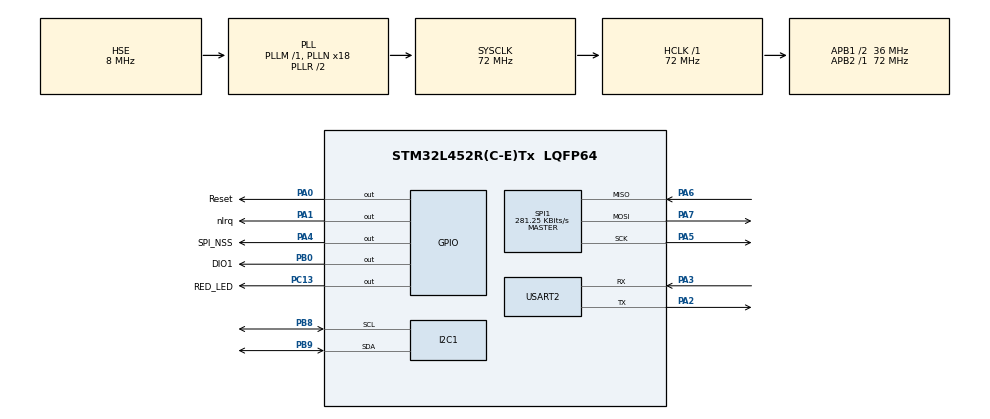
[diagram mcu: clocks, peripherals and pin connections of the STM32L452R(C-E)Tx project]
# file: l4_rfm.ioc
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I2C1.Timing=0x10808DD3
Mcu.Family=STM32L4
Mcu.Name=STM32L452R(C-E)Tx
Mcu.Package=LQFP64
NVIC.PriorityGroup=NVIC_PRIORITYGROUP_4
PA0.GPIO_Label=Reset
PA0.GPIO_ModeDefaultOutputPP=GPIO_MODE_OUTPUT_PP
PA0.GPIO_PuPd=GPIO_NOPULL
PA0.GPIO_Speed=GPIO_SPEED_FREQ_LOW
PA0.PinState=GPIO_PIN_RESET
PA0.Signal=GPIO_Output
PA1.GPIO_Label=nIrq
PA1.GPIO_ModeDefaultOutputPP=GPIO_MODE_OUTPUT_PP
PA1.GPIO_PuPd=GPIO_NOPULL
PA1.GPIO_Speed=GPIO_SPEED_FREQ_LOW
PA1.PinState=GPIO_PIN_RESET
PA1.Signal=GPIO_Output
PA13\ (JTMS/SWDIO).Signal=SYS_JTMS-SWDIO
PA14\ (JTCK/SWCLK).Signal=SYS_JTCK-SWCLK
PA2.GPIO_Mode=GPIO_MODE_AF_PP
PA2.GPIO_ModeDefaultPP=GPIO_MODE_AF_PP
PA2.GPIO_PuPd=GPIO_NOPULL
PA2.GPIO_Speed=GPIO_SPEED_FREQ_VERY_HIGH
PA2.Mode=Asynchronous
PA2.Signal=USART2_TX
PA3.GPIO_Mode=GPIO_MODE_AF_PP
PA3.GPIO_ModeDefaultPP=GPIO_MODE_AF_PP
PA3.GPIO_PuPd=GPIO_NOPULL
PA3.GPIO_Speed=GPIO_SPEED_FREQ_VERY_HIGH
PA3.Mode=Asynchronous
PA3.Signal=USART2_RX
PA4.GPIO_Label=SPI_NSS
PA4.GPIO_ModeDefaultOutputPP=GPIO_MODE_OUTPUT_PP
PA4.GPIO_PuPd=GPIO_NOPULL
PA4.GPIO_Speed=GPIO_SPEED_FREQ_LOW
PA4.PinState=GPIO_PIN_RESET
PA4.Signal=GPIO_Output
PA5.Mode=Full_Duplex_Master
PA5.Signal=SPI1_SCK
PA6.Mode=Full_Duplex_Master
PA6.Signal=SPI1_MISO
PA7.Mode=Full_Duplex_Master
PA7.Signal=SPI1_MOSI
PB0.GPIO_Label=DIO1
PB0.GPIO_ModeDefaultOutputPP=GPIO_MODE_OUTPUT_PP
PB0.GPIO_PuPd=GPIO_NOPULL
PB0.GPIO_Speed=GPIO_SPEED_FREQ_LOW
PB0.PinState=GPIO_PIN_RESET
PB0.Signal=GPIO_Output
PB3\ (JTDO/TRACESWO).Signal=SYS_JTDO-SWO
PB8.Mode=I2C
PB8.Signal=I2C1_SCL
PB9.Mode=I2C
PB9.Signal=I2C1_SDA
PC13.GPIO_Label=RED_LED
PC13.GPIO_ModeDefaultOutputPP=GPIO_MODE_OUTPUT_PP
PC13.GPIO_PuPd=GPIO_NOPULL
PC13.GPIO_Speed=GPIO_SPEED_FREQ_LOW
PC13.PinState=GPIO_PIN_RESET
PC13.Signal=GPIO_Output
PC14-OSC32_IN\ (PC14).Mode=LSE-External-Oscillator
PC14-OSC32_IN\ (PC14).Signal=RCC_OSC32_IN
PC15-OSC32_OUT\ (PC15).Mode=LSE-External-Oscillator
PC15-OSC32_OUT\ (PC15).Signal=RCC_OSC32_OUT
PH0-OSC_IN\ (PH0).Mode=HSE-External-Oscillator
PH0-OSC_IN\ (PH0).Signal=RCC_OSC_IN
PH1-OSC_OUT\ (PH1).Mode=HSE-External-Oscillator
PH1-OSC_OUT\ (PH1).Signal=RCC_OSC_OUT
ProjectManager.HeapSize=0x200
ProjectManager.StackSize=0x400
ProjectManager.TargetToolchain=STM32CubeIDE
RCC.ADCFreq_Value=32000000
RCC.AHBFreq_Value=72000000
RCC.APB1CLKDivider=RCC_HCLK_DIV2
RCC.APB1Freq_Value=36000000
RCC.APB1TimFreq_Value=72000000
RCC.APB2Freq_Value=72000000
RCC.APB2TimFreq_Value=72000000
RCC.CortexFreq_Value=72000000
RCC.HCLKFreq_Value=72000000
RCC.HSE_VALUE=8000000
RCC.HSI48_VALUE=48000000
RCC.HSI_VALUE=16000000
RCC.I2C1CLockSelection=RCC_I2C1CLKSOURCE_SYSCLK
RCC.MSI_VALUE=4000000
RCC.PLLN=18
RCC.PLLSourceVirtual=RCC_PLLSOURCE_HSE
RCC.PREFETCH_ENABLE=1
RCC.SYSCLKFreq_VALUE=72000000
RCC.SYSCLKSource=RCC_SYSCLKSOURCE_PLLCLK
RCC.USBFreq_Value=32000000
RCC.VCOOutputFreq_Value=144000000
SPI1.BaudRatePrescaler=SPI_BAUDRATEPRESCALER_256
SPI1.CalculateBaudRate=281.25 KBits/s
SPI1.DataSize=SPI_DATASIZE_8BIT
SPI1.Direction=SPI_DIRECTION_2LINES
SPI1.Mode=SPI_MODE_MASTER
SPI1.VirtualType=VM_MASTER
USART2.VirtualMode-Asynchronous=VM_ASYNC
board=NUCLEO-L452RE

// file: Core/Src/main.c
/* USER CODE BEGIN Header */
/**
  ******************************************************************************
  * @file           : main.c
  * @brief          : Main program body
  ******************************************************************************
  * @attention
  *
  * <h2><center>&copy; Copyright (c) 2020 STMicroelectronics.
  * All rights reserved.</center></h2>
  *
  * This software component is licensed by ST under BSD 3-Clause license,
  * the "License"; You may not use this file except in compliance with the
  * License. You may obtain a copy of the License at:
  *                        opensource.org/licenses/BSD-3-Clause
  *
  ******************************************************************************
  */
/* USER CODE END Header */

#include "main.h"
#include "stm32l4xx_hal_conf.h"
#include "connection.h"
#include "string.h"

I2C_HandleTypeDef hi2c1;

SPI_HandleTypeDef hspi1;

UART_HandleTypeDef huart2;

void SystemClock_Config(void);
static void MX_GPIO_Init(void);
static void MX_USART2_UART_Init(void);
static void MX_SPI1_Init(void);
static void MX_I2C1_Init(void);

int main(void)
{
  /* USER CODE BEGIN 1 */
	HAL_StatusTypeDef ret;
	//	uint8_t buf[12];
		int16_t val;
		float temp_c;//,transfer=0,a,b;

  /* USER CODE END 1 */

  /* MCU Configuration--------------------------------------------------------*/

  /* Reset of all peripherals, Initializes the Flash interface and the Systick. */
  HAL_Init();

  /* Configure the system clock */
  SystemClock_Config();

  /* Initialize all configured peripherals */
  MX_GPIO_Init();
  MX_USART2_UART_Init();
  MX_SPI1_Init();
  MX_I2C1_Init();

  /* Infinite loop */
  while (1)
  {

    /* USER CODE BEGIN 3 */
//	 connection(&transfer);
	 connection();
  }
  /* USER CODE END 3 */
}

void SystemClock_Config(void)
{
  RCC_OscInitTypeDef RCC_OscInitStruct = {0};
  RCC_ClkInitTypeDef RCC_ClkInitStruct = {0};
  RCC_PeriphCLKInitTypeDef PeriphClkInit = {0};

  /** Initializes the CPU, AHB and APB busses clocks
  */
  RCC_OscInitStruct.OscillatorType = RCC_OSCILLATORTYPE_HSE;
  RCC_OscInitStruct.HSEState = RCC_HSE_ON;
  RCC_OscInitStruct.PLL.PLLState = RCC_PLL_ON;
  RCC_OscInitStruct.PLL.PLLSource = RCC_PLLSOURCE_HSE;
  RCC_OscInitStruct.PLL.PLLM = 1;
  RCC_OscInitStruct.PLL.PLLN = 18;
  RCC_OscInitStruct.PLL.PLLP = RCC_PLLP_DIV7;
  RCC_OscInitStruct.PLL.PLLQ = RCC_PLLQ_DIV2;
  RCC_OscInitStruct.PLL.PLLR = RCC_PLLR_DIV2;
  if (HAL_RCC_OscConfig(&RCC_OscInitStruct) != HAL_OK)
  {
    Error_Handler();
  }
  /** Initializes the CPU, AHB and APB busses clocks
  */
  RCC_ClkInitStruct.ClockType = RCC_CLOCKTYPE_HCLK|RCC_CLOCKTYPE_SYSCLK
                              |RCC_CLOCKTYPE_PCLK1|RCC_CLOCKTYPE_PCLK2;
  RCC_ClkInitStruct.SYSCLKSource = RCC_SYSCLKSOURCE_PLLCLK;
  RCC_ClkInitStruct.AHBCLKDivider = RCC_SYSCLK_DIV1;
  RCC_ClkInitStruct.APB1CLKDivider = RCC_HCLK_DIV2;
  RCC_ClkInitStruct.APB2CLKDivider = RCC_HCLK_DIV1;

  if (HAL_RCC_ClockConfig(&RCC_ClkInitStruct, FLASH_LATENCY_4) != HAL_OK)
  {
    Error_Handler();
  }
  PeriphClkInit.PeriphClockSelection = RCC_PERIPHCLK_USART2|RCC_PERIPHCLK_I2C1;
  PeriphClkInit.Usart2ClockSelection = RCC_USART2CLKSOURCE_PCLK1;
  PeriphClkInit.I2c1ClockSelection = RCC_I2C1CLKSOURCE_SYSCLK;
  if (HAL_RCCEx_PeriphCLKConfig(&PeriphClkInit) != HAL_OK)
  {
    Error_Handler();
  }
  /** Configure the main internal regulator output voltage
  */
  if (HAL_PWREx_ControlVoltageScaling(PWR_REGULATOR_VOLTAGE_SCALE1) != HAL_OK)
  {
    Error_Handler();
  }
}

static void MX_I2C1_Init(void)
{

  hi2c1.Instance = I2C1;
  hi2c1.Init.Timing = 0x10808DD3;
  hi2c1.Init.OwnAddress1 = 0;
  hi2c1.Init.AddressingMode = I2C_ADDRESSINGMODE_7BIT;
  hi2c1.Init.DualAddressMode = I2C_DUALADDRESS_DISABLE;
  hi2c1.Init.OwnAddress2 = 0;
  hi2c1.Init.OwnAddress2Masks = I2C_OA2_NOMASK;
  hi2c1.Init.GeneralCallMode = I2C_GENERALCALL_DISABLE;
  hi2c1.Init.NoStretchMode = I2C_NOSTRETCH_DISABLE;
  if (HAL_I2C_Init(&hi2c1) != HAL_OK)
  {
    Error_Handler();
  }
  /** Configure Analogue filter
  */
  if (HAL_I2CEx_ConfigAnalogFilter(&hi2c1, I2C_ANALOGFILTER_ENABLE) != HAL_OK)
  {
    Error_Handler();
  }
  /** Configure Digital filter
  */
  if (HAL_I2CEx_ConfigDigitalFilter(&hi2c1, 0) != HAL_OK)
  {
    Error_Handler();
  }

}

static void MX_SPI1_Init(void)
{

  /* SPI1 parameter configuration*/
  hspi1.Instance = SPI1;
  hspi1.Init.Mode = SPI_MODE_MASTER;
  hspi1.Init.Direction = SPI_DIRECTION_2LINES;
  hspi1.Init.DataSize = SPI_DATASIZE_8BIT;
  hspi1.Init.CLKPolarity = SPI_POLARITY_LOW;
  hspi1.Init.CLKPhase = SPI_PHASE_1EDGE;
  hspi1.Init.NSS = SPI_NSS_SOFT;
  hspi1.Init.BaudRatePrescaler = SPI_BAUDRATEPRESCALER_256;
  hspi1.Init.FirstBit = SPI_FIRSTBIT_MSB;
  hspi1.Init.TIMode = SPI_TIMODE_DISABLE;
  hspi1.Init.CRCCalculation = SPI_CRCCALCULATION_DISABLE;
  hspi1.Init.CRCPolynomial = 7;
  hspi1.Init.CRCLength = SPI_CRC_LENGTH_DATASIZE;
  hspi1.Init.NSSPMode = SPI_NSS_PULSE_ENABLE;
  if (HAL_SPI_Init(&hspi1) != HAL_OK)
  {
    Error_Handler();
  }

}

static void MX_USART2_UART_Init(void)
{

  huart2.Instance = USART2;
  huart2.Init.BaudRate = 115200;
  huart2.Init.WordLength = UART_WORDLENGTH_8B;
  huart2.Init.StopBits = UART_STOPBITS_1;
  huart2.Init.Parity = UART_PARITY_NONE;
  huart2.Init.Mode = UART_MODE_TX_RX;
  huart2.Init.HwFlowCtl = UART_HWCONTROL_NONE;
  huart2.Init.OverSampling = UART_OVERSAMPLING_16;
  huart2.Init.OneBitSampling = UART_ONE_BIT_SAMPLE_DISABLE;
  huart2.AdvancedInit.AdvFeatureInit = UART_ADVFEATURE_NO_INIT;
  if (HAL_UART_Init(&huart2) != HAL_OK)
  {
    Error_Handler();
  }

}

static void MX_GPIO_Init(void)
{
  GPIO_InitTypeDef GPIO_InitStruct = {0};

  /* GPIO Ports Clock Enable */
  __HAL_RCC_GPIOC_CLK_ENABLE();
  __HAL_RCC_GPIOH_CLK_ENABLE();
  __HAL_RCC_GPIOA_CLK_ENABLE();
  __HAL_RCC_GPIOB_CLK_ENABLE();

  /*Configure GPIO pin Output Level */
  HAL_GPIO_WritePin(RED_LED_GPIO_Port, RED_LED_Pin, GPIO_PIN_RESET);

  /*Configure GPIO pin Output Level */
  HAL_GPIO_WritePin(GPIOA, Reset_Pin|nIrq_Pin|SPI_NSS_Pin, GPIO_PIN_RESET);

  /*Configure GPIO pin Output Level */
  HAL_GPIO_WritePin(DIO1_GPIO_Port, DIO1_Pin, GPIO_PIN_RESET);

  /*Configure GPIO pin : RED_LED_Pin */
  GPIO_InitStruct.Pin = RED_LED_Pin;
  GPIO_InitStruct.Mode = GPIO_MODE_OUTPUT_PP;
  GPIO_InitStruct.Pull = GPIO_NOPULL;
  GPIO_InitStruct.Speed = GPIO_SPEED_FREQ_LOW;
  HAL_GPIO_Init(RED_LED_GPIO_Port, &GPIO_InitStruct);

  /*Configure GPIO pins : Reset_Pin nIrq_Pin SPI_NSS_Pin */
  GPIO_InitStruct.Pin = Reset_Pin|nIrq_Pin|SPI_NSS_Pin;
  GPIO_InitStruct.Mode = GPIO_MODE_OUTPUT_PP;
  GPIO_InitStruct.Pull = GPIO_NOPULL;
  GPIO_InitStruct.Speed = GPIO_SPEED_FREQ_LOW;
  HAL_GPIO_Init(GPIOA, &GPIO_InitStruct);

  /*Configure GPIO pin : DIO1_Pin */
  GPIO_InitStruct.Pin = DIO1_Pin;
  GPIO_InitStruct.Mode = GPIO_MODE_OUTPUT_PP;
  GPIO_InitStruct.Pull = GPIO_NOPULL;
  GPIO_InitStruct.Speed = GPIO_SPEED_FREQ_LOW;
  HAL_GPIO_Init(DIO1_GPIO_Port, &GPIO_InitStruct);

}

void Error_Handler(void)
{
}

/************************ (C) COPYRIGHT STMicroelectronics *****END OF FILE****/
